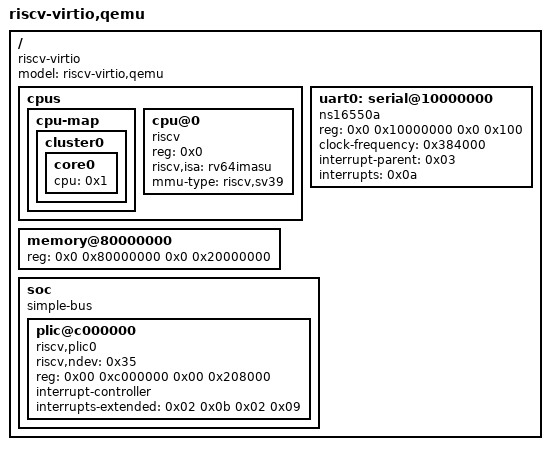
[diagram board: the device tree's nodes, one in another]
/* https://github.com/devicetree-org/devicetree-specification/tree/main/source */
/* https://github.com/torvalds/linux/tree/master/Documentation/devicetree/bindings/riscv */

/dts-v1/;

/ {
	#address-cells = <0x2>;
	#size-cells = <0x2>;
	compatible = "riscv-virtio";
	model = "riscv-virtio,qemu";

	cpus {
		#address-cells = <0x1>;
		#size-cells = <0x0>;

		cpu-map {
			cluster0 {
				core0 {
					cpu = <0x1>;
				};
			};
		};

		cpu@0 {
			phandle = <0x1>;
			device_type = "cpu";
			reg = <0x0>;
			compatible = "riscv";
			riscv,isa = "rv64imasu";
			mmu-type = "riscv,sv39";
		};
	};

	memory@80000000 {
		device_type = "memory";
		reg = <0x0 0x80000000 0x0 0x20000000>;
	};

    uart0: serial@10000000 {
        compatible = "ns16550a";
        reg = <0x0 0x10000000 0x0 0x100>;
        clock-frequency = <0x384000>;
        interrupt-parent = <0x03>;
        interrupts = <0x0a>;
    };

	soc {
        #address-cells = <0x02>;
        #size-cells = <0x02>;
        compatible = "simple-bus";
        ranges;

        plic@c000000 {
           	phandle = <0x03>;
            #interrupt-cells = <0x01>;
           	#address-cells = <0x00>;
           	riscv,ndev = <0x35>;
           	reg = <0x00 0xc000000 0x00 0x208000>;
            interrupt-controller;
           	compatible = "riscv,plic0";
           	interrupts-extended = < 0x02 0x0b 0x02 0x09 >;
        };
	}
};
